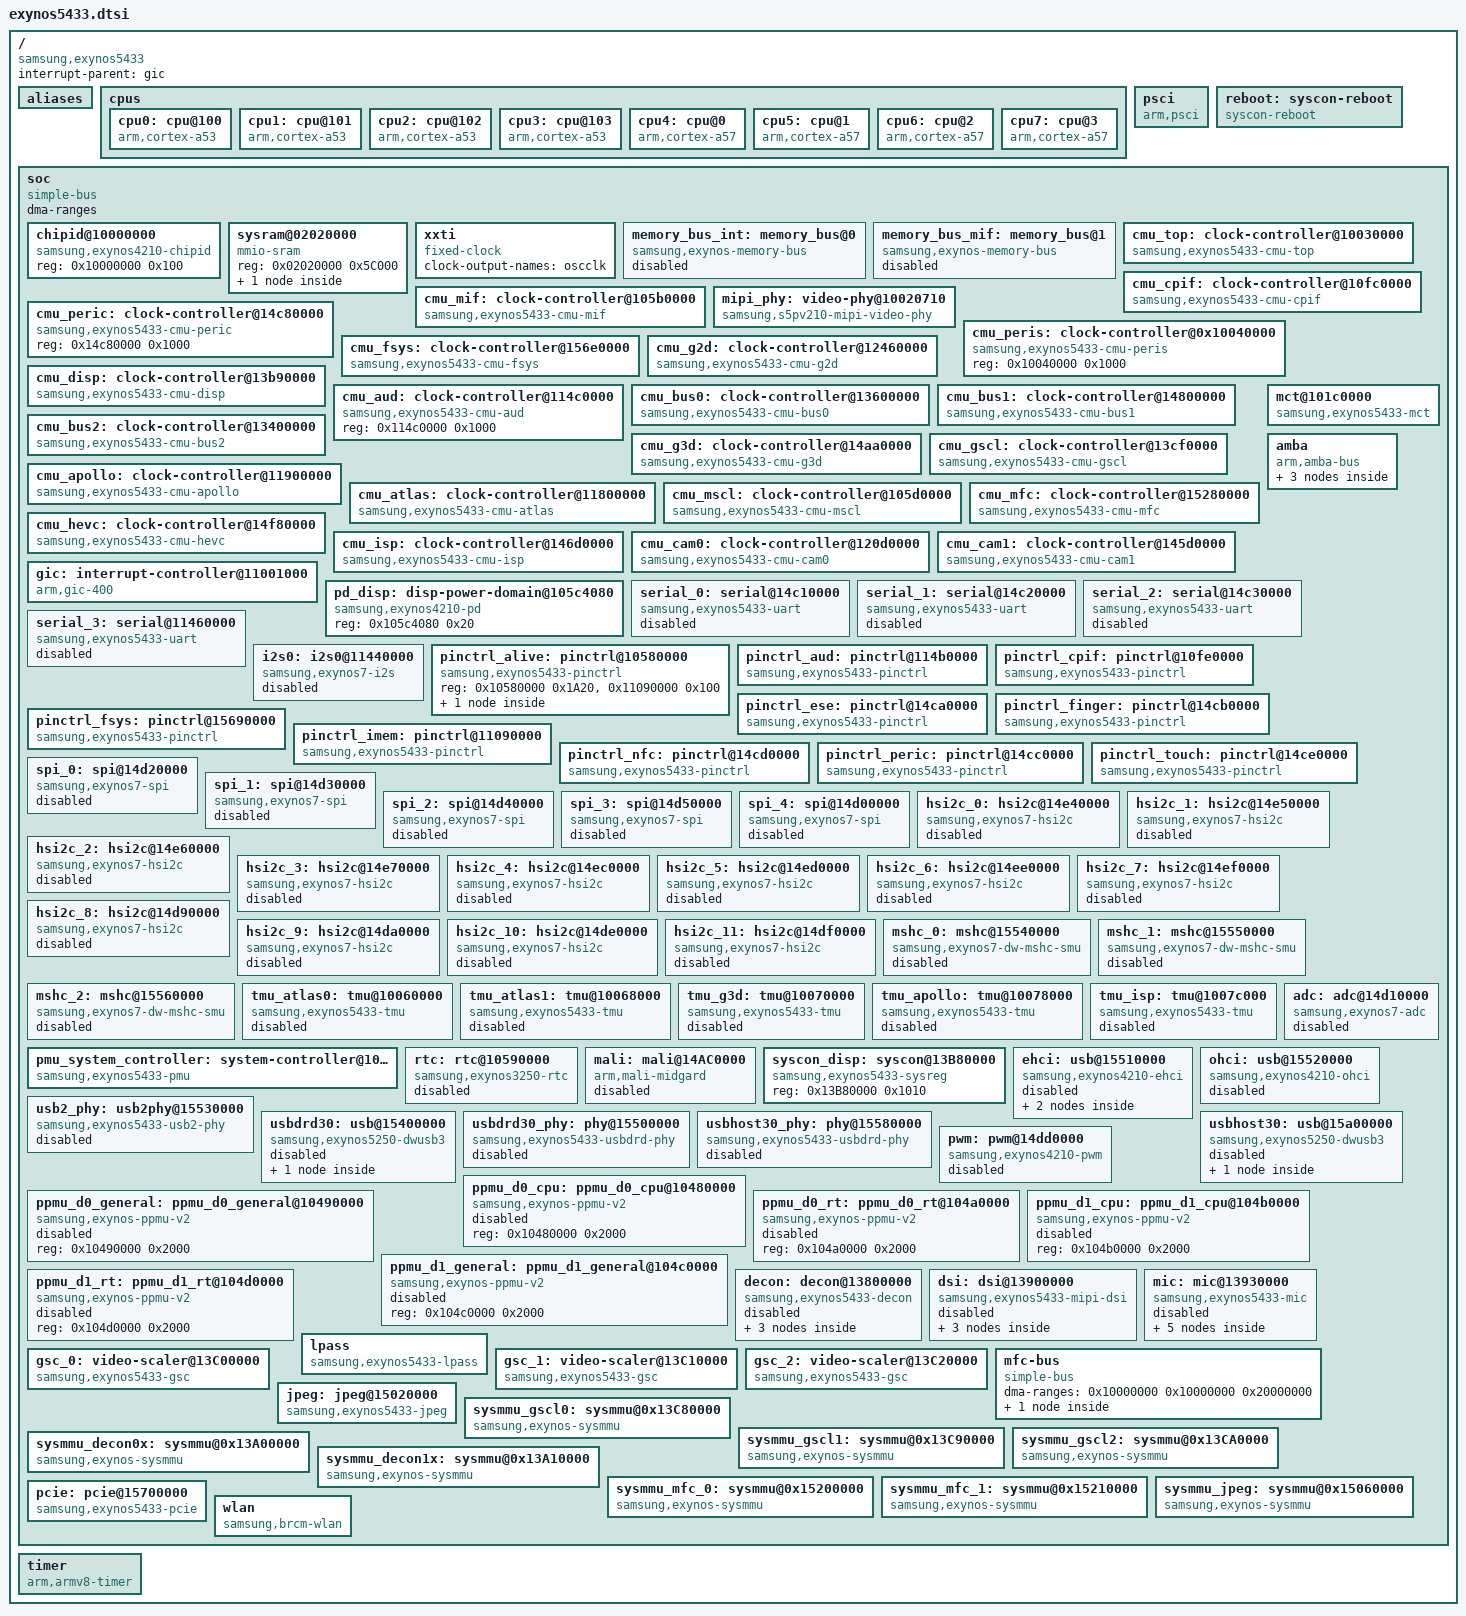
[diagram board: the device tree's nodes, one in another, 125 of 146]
/*
 * Samsung's Exynos5433 SoC device tree source
 *
 * Copyright (c) 2015 Samsung Electronics Co., Ltd.
 *		http://www.samsung.com
 *
 * Samsung's Exynos5433 SoC device nodes are listed in this file. Exynos5433
 * based board files can include this file and provide values for board specfic
 * bindings.
 *
 * Note: This file does not include device nodes for all the controllers in
 * Exynos5433 SoC. As device tree coverage for Exynos5433 increases, additional
 * nodes can be added to this file.
 *
 * This program is free software; you can redistribute it and/or modify
 * it under the terms of the GNU General Public License version 2 as
 * published by the Free Software Foundation.
 */

#include <dt-bindings/clock/exynos5433.h>

/ {
	compatible = "samsung,exynos5433";
	#address-cells = <2>;
	#size-cells = <2>;

	interrupt-parent = <&gic>;

	aliases {
		gsc0 = &gsc_0;
		gsc1 = &gsc_1;
		gsc2 = &gsc_2;
	};

	cpus {
		#address-cells = <1>;
		#size-cells = <0>;

		cpu0: cpu@100 {
			device_type = "cpu";
			compatible = "arm,cortex-a53", "arm,armv8";
			enable-method = "psci";
			reg = <0x100>;

			clocks = <&cmu_apollo CLK_SCLK_APOLLO>;
			clock-names = "cpu-cluster.1";
			clock-latency = <100000>;
			#cooling-cells = <2>;

			operating-points = <
				1300000 1150000
				1200000 1112500
				1100000 1112500
				1000000 1075000
				900000  1050000
				800000  1000000
				700000  975000
				600000  950000
				500000  925000
				400000  900000
			>;
			suspend-freq = <1200000>;
		};

		cpu1: cpu@101 {
			device_type = "cpu";
			compatible = "arm,cortex-a53", "arm,armv8";
			enable-method = "psci";
			reg = <0x101>;
		};

		cpu2: cpu@102 {
			device_type = "cpu";
			compatible = "arm,cortex-a53", "arm,armv8";
			enable-method = "psci";
			reg = <0x102>;
		};

		cpu3: cpu@103 {
			device_type = "cpu";
			compatible = "arm,cortex-a53", "arm,armv8";
			enable-method = "psci";
			reg = <0x103>;
		};

		cpu4: cpu@0 {
			device_type = "cpu";
			compatible = "arm,cortex-a57", "arm,armv8";
			enable-method = "psci";
			reg = <0x0>;

			clocks = <&cmu_atlas CLK_SCLK_ATLAS>;
			clock-names = "cpu-cluster.0";
			clock-latency = <100000>;
			#cooling-cells = <2>;

			operating-points = <
				1900000 1262500
				1800000 1212500
				1700000 1175000
				1600000 1137500
				1500000 1125000
				1400000 1087500
				1300000 1062500
				1200000 1037500
				1100000 1012500
				1000000 975000
				900000  937500
				800000  912500
				700000  912500
			>;
			suspend-freq = <1200000>;
		};

		cpu5: cpu@1 {
			device_type = "cpu";
			compatible = "arm,cortex-a57", "arm,armv8";
			enable-method = "psci";
			reg = <0x1>;
		};

		cpu6: cpu@2 {
			device_type = "cpu";
			compatible = "arm,cortex-a57", "arm,armv8";
			enable-method = "psci";
			reg = <0x2>;
		};

		cpu7: cpu@3 {
			device_type = "cpu";
			compatible = "arm,cortex-a57", "arm,armv8";
			enable-method = "psci";
			reg = <0x3>;
		};
	};

	psci {
		compatible = "arm,psci";
		method = "smc";
		cpu_suspend =  <0xC4000001>;
		cpu_off = <0x84000002>;
		cpu_on = <0xC4000003>;
	};

	reboot: syscon-reboot {
		compatible = "syscon-reboot";
		regmap = <&pmu_system_controller>;
		offset = <0x400>;
		mask = <0x1>;
	};

	soc: soc {
		compatible = "simple-bus";
		#address-cells = <1>;
		#size-cells = <1>;
		ranges = <0x0 0x0 0x0 0x18000000>;
		dma-ranges;

		chipid@10000000 {
			compatible = "samsung,exynos4210-chipid";
			reg = <0x10000000 0x100>;
		};

		sysram@02020000 {
			compatible = "mmio-sram";
			reg = <0x02020000 0x5C000>;
			#address-cells = <1>;
			#size-cells = <1>;
			ranges = <0 0x02020000 0x5C000>;

			smp-sysram@5B000 {
				compatible = "samsung,exynos5433-sysram-ns";
				reg = <0x5B000 0x1000>;
			};
		};

		xxti: xxti {
			compatible = "fixed-clock";
			clock-output-names = "oscclk";
			#clock-cells = <0>;
		};

		memory_bus_int: memory_bus@0 {
			compatible = "samsung,exynos-memory-bus";
			operating-points = <
				400000 1075000
				334000 1025000
				267000 1000000
				200000 975000
				160000 962500
				133000 950000
				100000 937500>;
			status = "disabled";
		};

		memory_bus_mif: memory_bus@1 {
			compatible = "samsung,exynos-memory-bus";
			operating-points = <
				825000 1050000
				667000 1000000
				543000 975000
				413000 950000
				272000 950000
				222000 950000
				167000 925000
				136000 900000
				109000 875000
				78000  875000>;
			status = "disabled";
		};

		cmu_top: clock-controller@10030000 {
			compatible = "samsung,exynos5433-cmu-top";
			reg = <0x10030000 0x1000>;
			#clock-cells = <1>;

			clock-names = "oscclk",
				"sclk_mphy_pll",
				"sclk_mfc_pll",
				"sclk_bus_pll";
			clocks = <&xxti>,
			       <&cmu_cpif CLK_SCLK_MPHY_PLL>,
			       <&cmu_mif CLK_SCLK_MFC_PLL>,
			       <&cmu_mif CLK_SCLK_BUS_PLL>;
		};

		cmu_cpif: clock-controller@10fc0000 {
			compatible = "samsung,exynos5433-cmu-cpif";
			reg = <0x10fc0000 0x1000>;
			#clock-cells = <1>;

			clock-names = "oscclk";
			clocks = <&xxti>;
		};

		cmu_mif: clock-controller@105b0000 {
			compatible = "samsung,exynos5433-cmu-mif";
			reg = <0x105b0000 0x2000>;
			#clock-cells = <1>;

			clock-names = "oscclk",
				"sclk_mphy_pll";
			clocks = <&xxti>,
			       <&cmu_cpif CLK_SCLK_MPHY_PLL>;
		};

		mipi_phy: video-phy@10020710 {
			compatible = "samsung,s5pv210-mipi-video-phy";
			reg = <0x10020710 8>;
			#phy-cells = <1>;
			syscon = <&pmu_system_controller>;
		};

		cmu_peric: clock-controller@14c80000 {
			compatible = "samsung,exynos5433-cmu-peric";
			reg = <0x14c80000 0x1000>;
			#clock-cells = <1>;
		};

		cmu_peris: clock-controller@0x10040000 {
			compatible = "samsung,exynos5433-cmu-peris";
			reg = <0x10040000 0x1000>;
			#clock-cells = <1>;
		};

		cmu_fsys: clock-controller@156e0000 {
			compatible = "samsung,exynos5433-cmu-fsys";
			reg = <0x156e0000 0x1000>;
			#clock-cells = <1>;

			clock-names = "oscclk",
				"sclk_ufs_mphy",
				"div_aclk_fsys_200",
				"sclk_pcie_100_fsys",
				"sclk_ufsunipro_fsys",
				"sclk_mmc2_fsys",
				"sclk_mmc1_fsys",
				"sclk_mmc0_fsys",
				"sclk_usbhost30_fsys",
				"sclk_usbdrd30_fsys";
			clocks = <&xxti>,
			       <&cmu_cpif CLK_SCLK_UFS_MPHY>,
			       <&cmu_top CLK_DIV_ACLK_FSYS_200>,
			       <&cmu_top CLK_SCLK_PCIE_100_FSYS>,
			       <&cmu_top CLK_SCLK_UFSUNIPRO_FSYS>,
			       <&cmu_top CLK_SCLK_MMC2_FSYS>,
			       <&cmu_top CLK_SCLK_MMC1_FSYS>,
			       <&cmu_top CLK_SCLK_MMC0_FSYS>,
			       <&cmu_top CLK_SCLK_USBHOST30_FSYS>,
			       <&cmu_top CLK_SCLK_USBDRD30_FSYS>;
		};

		cmu_g2d: clock-controller@12460000 {
			compatible = "samsung,exynos5433-cmu-g2d";
			reg = <0x12460000 0x1000>;
			#clock-cells = <1>;

			clock-names = "oscclk",
				"aclk_g2d_266",
				"aclk_g2d_400";
			clocks = <&xxti>,
			       <&cmu_top CLK_ACLK_G2D_266>,
			       <&cmu_top CLK_ACLK_G2D_400>;
		};

		cmu_disp: clock-controller@13b90000 {
			compatible = "samsung,exynos5433-cmu-disp";
			reg = <0x13b90000 0x1000>;
			#clock-cells = <1>;

			clock-names = "oscclk",
				"sclk_dsim1_disp",
				"sclk_dsim0_disp",
				"sclk_dsd_disp",
				"sclk_decon_tv_eclk_disp",
				"sclk_decon_vclk_disp",
				"sclk_decon_eclk_disp",
				"sclk_decon_tv_vclk_disp",
				"aclk_disp_333";
			clocks = <&xxti>,
			       <&cmu_mif CLK_SCLK_DSIM1_DISP>,
			       <&cmu_mif CLK_SCLK_DSIM0_DISP>,
			       <&cmu_mif CLK_SCLK_DSD_DISP>,
			       <&cmu_mif CLK_SCLK_DECON_TV_ECLK_DISP>,
			       <&cmu_mif CLK_SCLK_DECON_VCLK_DISP>,
			       <&cmu_mif CLK_SCLK_DECON_ECLK_DISP>,
			       <&cmu_mif CLK_SCLK_DECON_TV_VCLK_DISP>,
			       <&cmu_mif CLK_ACLK_DISP_333>;
			power-domains = <&pd_disp>;
		};

		cmu_aud: clock-controller@114c0000 {
			compatible = "samsung,exynos5433-cmu-aud";
			reg = <0x114c0000 0x1000>;
			#clock-cells = <1>;
		};

		cmu_bus0: clock-controller@13600000 {
			compatible = "samsung,exynos5433-cmu-bus0";
			reg = <0x13600000 0x1000>;
			#clock-cells = <1>;

			clock-names = "aclk_bus0_400";
			clocks = <&cmu_top CLK_ACLK_BUS0_400>;
		};

		cmu_bus1: clock-controller@14800000 {
			compatible = "samsung,exynos5433-cmu-bus1";
			reg = <0x14800000 0x1000>;
			#clock-cells = <1>;

			clock-names = "aclk_bus1_400";
			clocks = <&cmu_top CLK_ACLK_BUS1_400>;
		};

		cmu_bus2: clock-controller@13400000 {
			compatible = "samsung,exynos5433-cmu-bus2";
			reg = <0x13400000 0x1000>;
			#clock-cells = <1>;

			clock-names = "oscclk", "aclk_bus2_400";
			clocks = <&xxti>, <&cmu_mif CLK_ACLK_BUS2_400>;
		};

		cmu_g3d: clock-controller@14aa0000 {
			compatible = "samsung,exynos5433-cmu-g3d";
			reg = <0x14aa0000 0x2000>;
			#clock-cells = <1>;

			clock-names = "oscclk", "aclk_g3d_400";
			clocks = <&xxti>, <&cmu_top CLK_ACLK_G3D_400>;
		};

		cmu_gscl: clock-controller@13cf0000 {
			compatible = "samsung,exynos5433-cmu-gscl";
			reg = <0x13cf0000 0x1000>;
			#clock-cells = <1>;

			clock-names = "oscclk",
				"aclk_gscl_111",
				"aclk_gscl_333";
			clocks = <&xxti>,
				<&cmu_top CLK_ACLK_GSCL_111>,
				<&cmu_top CLK_ACLK_GSCL_333>;
		};

		cmu_apollo: clock-controller@11900000 {
			compatible = "samsung,exynos5433-cmu-apollo";
			reg = <0x11900000 0x2000>;
			#clock-cells = <1>;

			clock-names = "oscclk", "sclk_bus_pll_apollo";
			clocks = <&xxti>, <&cmu_mif CLK_SCLK_BUS_PLL_APOLLO>;
		};

		cmu_atlas: clock-controller@11800000 {
			compatible = "samsung,exynos5433-cmu-atlas";
			reg = <0x11800000 0x2000>;
			#clock-cells = <1>;

			clock-names = "oscclk", "sclk_bus_pll_atlas";
			clocks = <&xxti>, <&cmu_mif CLK_SCLK_BUS_PLL_ATLAS>;
		};

		cmu_mscl: clock-controller@105d0000 {
			compatible = "samsung,exynos5433-cmu-mscl";
			reg = <0x150d0000 0x1000>;
			#clock-cells = <1>;

			clock-names = "oscclk",
				"sclk_jpeg_mscl",
				"aclk_mscl_400";
			clocks = <&xxti>,
			       <&cmu_top CLK_SCLK_JPEG_MSCL>,
			       <&cmu_top CLK_ACLK_MSCL_400>;
		};

		cmu_mfc: clock-controller@15280000 {
			compatible = "samsung,exynos5433-cmu-mfc";
			reg = <0x15280000 0x1000>;
			#clock-cells = <1>;

			clock-names = "oscclk", "aclk_mfc_400";
			clocks = <&xxti>, <&cmu_top CLK_ACLK_MFC_400>;
		};

		cmu_hevc: clock-controller@14f80000 {
			compatible = "samsung,exynos5433-cmu-hevc";
			reg = <0x14f80000 0x1000>;
			#clock-cells = <1>;

			clock-names = "oscclk", "aclk_hevc_400";
			clocks = <&xxti>, <&cmu_top CLK_ACLK_HEVC_400>;
		};

		cmu_isp: clock-controller@146d0000 {
			compatible = "samsung,exynos5433-cmu-isp";
			reg = <0x146d0000 0x1000>;
			#clock-cells = <1>;

			clock-names = "oscclk",
				"aclk_isp_dis_400",
				"aclk_isp_400";
			clocks = <&xxti>,
			       <&cmu_top CLK_ACLK_ISP_DIS_400>,
			       <&cmu_top CLK_ACLK_ISP_400>;
		};

		cmu_cam0: clock-controller@120d0000 {
			compatible = "samsung,exynos5433-cmu-cam0";
			reg = <0x120d0000 0x1000>;
			#clock-cells = <1>;

			clock-names = "oscclk",
				"aclk_cam0_333",
				"aclk_cam0_400",
				"aclk_cam0_552";
			clocks = <&xxti>,
			       <&cmu_top CLK_ACLK_CAM0_333>,
			       <&cmu_top CLK_ACLK_CAM0_400>,
			       <&cmu_top CLK_ACLK_CAM0_552>;
		};

		cmu_cam1: clock-controller@145d0000 {
			compatible = "samsung,exynos5433-cmu-cam1";
			reg = <0x145d0000 0x1000>;
			#clock-cells = <1>;

			clock-names = "oscclk",
				"sclk_isp_uart_cam1",
				"sclk_isp_spi1_cam1",
				"sclk_isp_spi0_cam1",
				"aclk_cam1_333",
				"aclk_cam1_400",
				"aclk_cam1_552";
			clocks = <&xxti>,
			       <&cmu_top CLK_SCLK_ISP_UART_CAM1>,
			       <&cmu_top CLK_SCLK_ISP_SPI1_CAM1>,
			       <&cmu_top CLK_SCLK_ISP_SPI0_CAM1>,
			       <&cmu_top CLK_ACLK_CAM1_333>,
			       <&cmu_top CLK_ACLK_CAM1_400>,
			       <&cmu_top CLK_ACLK_CAM1_552>;
		};

		mct@101c0000 {
			compatible = "samsung,exynos5433-mct",
				     "samsung,exynos4210-mct";
			reg = <0x101c0000 0x800>;
			interrupts = <0 102 0>, <0 103 0>, <0 104 0>, <0 105 0>,
				<0 106 0>, <0 107 0>, <0 108 0>, <0 109 0>,
				<0 110 0>, <0 111 0>, <0 112 0>, <0 113 0>;
			clocks = <&xxti>,
			         <&cmu_peris CLK_PCLK_MCT>;
			clock-names = "fin_pll", "mct";
		};

		gic:interrupt-controller@11001000 {
			compatible = "arm,gic-400";
			#interrupt-cells = <3>;
			interrupt-controller;
			reg =	<0x11001000 0x1000>,
				<0x11002000 0x2000>,
				<0x11004000 0x2000>,
				<0x11006000 0x2000>;
			interrupts = <1 9 0xf04>;
		};

		amba {
			compatible = "arm,amba-bus";
			#address-cells = <1>;
			#size-cells = <1>;
			ranges;

			pdma0: pdma@15610000 {
				compatible = "arm,pl330", "arm,primecell";
				reg = <0x15610000 0x1000>;
				interrupts = <0 228 0>;
				clocks = <&cmu_fsys CLK_PDMA0>;
				clock-names = "apb_pclk";
				#dma-cells = <1>;
				#dma-channels = <8>;
				#dma-requests = <32>;
			};

			pdma1: pdma@15600000 {
				compatible = "arm,pl330", "arm,primecell";
				reg = <0x15600000 0x1000>;
				interrupts = <0 246 0>;
				clocks = <&cmu_fsys CLK_PDMA1>;
				clock-names = "apb_pclk";
				#dma-cells = <1>;
				#dma-channels = <8>;
				#dma-requests = <32>;
			};

			adma: adma@11420000 {
				compatible = "arm,pl330", "arm,primecell";
				reg = <0x11420000 0x1000>;
				interrupts = <0 73 0>;
				clocks = <&cmu_aud CLK_ACLK_DMAC>;
				clock-names = "apb_pclk";
				#dma-cells = <1>;
				#dma-channels = <8>;
				#dma-requests = <32>;
			};
		};

		pd_disp: disp-power-domain@105c4080 {
			compatible = "samsung,exynos4210-pd";
			reg = <0x105c4080 0x20>;
			#power-domain-cells = <0>;
		};

		serial_0: serial@14c10000 {
			compatible = "samsung,exynos5433-uart";
			reg = <0x14c10000 0x100>;
			interrupts = <0 421 0>;
			clocks = <&cmu_peric CLK_PCLK_UART0>,
				 <&cmu_peric CLK_SCLK_UART0>;
			clock-names = "uart", "clk_uart_baud0";
			pinctrl-names = "default";
			pinctrl-0 = <&uart0_bus>;
			status = "disabled";
		};

		serial_1: serial@14c20000 {
			compatible = "samsung,exynos5433-uart";
			reg = <0x14c20000 0x100>;
			interrupts = <0 422 0>;
			clocks = <&cmu_peric CLK_PCLK_UART1>,
				 <&cmu_peric CLK_SCLK_UART1>;
			clock-names = "uart", "clk_uart_baud0";
			pinctrl-names = "default";
			pinctrl-0 = <&uart1_bus>;
			status = "disabled";
		};

		serial_2: serial@14c30000 {
			compatible = "samsung,exynos5433-uart";
			reg = <0x14c30000 0x100>;
			interrupts = <0 423 0>;
			clocks = <&cmu_peric CLK_PCLK_UART2>,
				 <&cmu_peric CLK_SCLK_UART2>;
			clock-names = "uart", "clk_uart_baud0";
			pinctrl-names = "default";
			pinctrl-0 = <&uart2_bus>;
			status = "disabled";
		};

		serial_3: serial@11460000 {
			compatible = "samsung,exynos5433-uart";
			reg = <0x11460000 0x100>;
			interrupts = <0 67 0>;
			clocks = <&cmu_aud CLK_PCLK_AUD_UART>,
				 <&cmu_aud CLK_SCLK_AUD_UART>;
			clock-names = "uart", "clk_uart_baud0";
			pinctrl-names = "default";
			pinctrl-0 = <&uart_aud_bus>;
			status = "disabled";
		};

		i2s0: i2s0@11440000 {
			compatible = "samsung,exynos7-i2s";
			reg = <0x11440000 0x100>;
			dmas = <&adma 0 &adma 2>;
			dma-names = "tx", "rx";
			interrupts = <0 70 0>;
			#address-cells = <1>;
			#size-cells = <0>;
			clocks = <&cmu_aud CLK_PCLK_AUD_I2S>,
				 <&cmu_aud CLK_SCLK_AUD_I2S>,
				 <&cmu_aud CLK_SCLK_I2S_BCLK>;
			clock-names = "iis", "i2s_opclk0", "i2s_opclk1";
			pinctrl-names = "default";
			pinctrl-0 = <&i2s0_bus>;
			status = "disabled";
		};

		pinctrl_alive: pinctrl@10580000 {
			compatible = "samsung,exynos5433-pinctrl";
			reg = <0x10580000 0x1A20>, <0x11090000 0x100>;

			wakeup-interrupt-controller {
				compatible = "samsung,exynos7-wakeup-eint";
				interrupts = <0 16 0>;
			};
		};

		pinctrl_aud: pinctrl@114b0000 {
			compatible = "samsung,exynos5433-pinctrl";
			reg = <0x114b0000 0x1000>;
			interrupts = <0 68 0>;
		};

		pinctrl_cpif: pinctrl@10fe0000 {
			compatible = "samsung,exynos5433-pinctrl";
			reg = <0x10fe0000 0x1000>;
			interrupts = <0 179 0>;
		};

		pinctrl_ese: pinctrl@14ca0000 {
			compatible = "samsung,exynos5433-pinctrl";
			reg = <0x14ca0000 0x1000>;
			interrupts = <0 413 0>;
		};

		pinctrl_finger: pinctrl@14cb0000 {
			compatible = "samsung,exynos5433-pinctrl";
			reg = <0x14cb0000 0x1000>;
			interrupts = <0 414 0>;
		};

		pinctrl_fsys: pinctrl@15690000 {
			compatible = "samsung,exynos5433-pinctrl";
			reg = <0x15690000 0x1000>;
			interrupts = <0 229 0>;
		};

		pinctrl_imem: pinctrl@11090000 {
			compatible = "samsung,exynos5433-pinctrl";
			reg = <0x11090000 0x1000>;
			interrupts = <0 325 0>;
		};

		pinctrl_nfc: pinctrl@14cd0000 {
			compatible = "samsung,exynos5433-pinctrl";
			reg = <0x14cd0000 0x1000>;
			interrupts = <0 441 0>;
		};

		pinctrl_peric: pinctrl@14cc0000 {
			compatible = "samsung,exynos5433-pinctrl";
			reg = <0x14cc0000 0x1100>;
			interrupts = <0 440 0>;
		};

		pinctrl_touch: pinctrl@14ce0000 {
			compatible = "samsung,exynos5433-pinctrl";
			reg = <0x14ce0000 0x1100>;
			interrupts = <0 442 0>;
		};

		spi_0: spi@14d20000 {
			compatible = "samsung,exynos7-spi";
			reg = <0x14d20000 0x100>;
			interrupts = <0 432 0>;
			dmas = <&pdma0 9>, <&pdma0 8>;
			dma-names = "tx", "rx";
			#address-cells = <1>;
			#size-cells = <0>;
			clocks = <&cmu_peric CLK_PCLK_SPI0>,
				 <&cmu_top CLK_SCLK_SPI0_PERIC>;
			clock-names = "spi", "spi_busclk0";
			samsung,spi-src-clk = <0>;
			pinctrl-names = "default";
			pinctrl-0 = <&spi0_bus>;
			status = "disabled";
		};

		spi_1: spi@14d30000 {
			compatible = "samsung,exynos7-spi";
			reg = <0x14d30000 0x100>;
			interrupts = <0 433 0>;
			dmas = <&pdma0 11>, <&pdma0 10>;
			dma-names = "tx", "rx";
			#address-cells = <1>;
			#size-cells = <0>;
			clocks = <&cmu_peric CLK_PCLK_SPI1>,
				 <&cmu_top CLK_SCLK_SPI1_PERIC>;
			clock-names = "spi", "spi_busclk0";
			samsung,spi-src-clk = <0>;
			pinctrl-names = "default";
			pinctrl-0 = <&spi1_bus>;
			status = "disabled";
		};

		spi_2: spi@14d40000 {
			compatible = "samsung,exynos7-spi";
			reg = <0x14d40000 0x100>;
			interrupts = <0 434 0>;
			dmas = <&pdma0 13>, <&pdma0 12>;
			dma-names = "tx", "rx";
			#address-cells = <1>;
			#size-cells = <0>;
			clocks = <&cmu_peric CLK_PCLK_SPI2>,
				 <&cmu_top CLK_SCLK_SPI2_PERIC>;
			clock-names = "spi", "spi_busclk0";
			samsung,spi-src-clk = <0>;
			pinctrl-names = "default";
			pinctrl-0 = <&spi2_bus>;
			status = "disabled";
		};

		spi_3: spi@14d50000 {
			compatible = "samsung,exynos7-spi";
			reg = <0x14d50000 0x100>;
			interrupts = <0 447 0>;
			dmas = <&pdma0 23>, <&pdma0 22>;
			dma-names = "tx", "rx";
			#address-cells = <1>;
			#size-cells = <0>;
			clocks = <&cmu_peric CLK_PCLK_SPI3>,
				 <&cmu_top CLK_SCLK_SPI3_PERIC>;
			clock-names = "spi", "spi_busclk0";
			samsung,spi-src-clk = <0>;
			pinctrl-names = "default";
			pinctrl-0 = <&spi3_bus>;
			status = "disabled";
		};

		spi_4: spi@14d00000 {
			compatible = "samsung,exynos7-spi";
			reg = <0x14d00000 0x100>;
			interrupts = <0 412 0>;
			dmas = <&pdma0 25>, <&pdma0 24>;
			dma-names = "tx", "rx";
			#address-cells = <1>;
			#size-cells = <0>;
			clocks = <&cmu_peric CLK_PCLK_SPI4>,
				 <&cmu_top CLK_SCLK_SPI4_PERIC>;
			clock-names = "spi", "spi_busclk0";
			samsung,spi-src-clk = <0>;
			pinctrl-names = "default";
			pinctrl-0 = <&spi4_bus>;
			status = "disabled";
		};

		hsi2c_0: hsi2c@14e40000 {
			compatible = "samsung,exynos7-hsi2c";
			reg = <0x14e40000 0x1000>;
			interrupts = <0 428 0>;
			#address-cells = <1>;
			#size-cells = <0>;
			pinctrl-names = "default";
			pinctrl-0 = <&hs_i2c0_bus>;
			clocks = <&cmu_peric CLK_PCLK_HSI2C0>;
			clock-names = "hsi2c";
			status = "disabled";
		};

		hsi2c_1: hsi2c@14e50000 {
			compatible = "samsung,exynos7-hsi2c";
			reg = <0x14e50000 0x1000>;
			interrupts = <0 429 0>;
			#address-cells = <1>;
			#size-cells = <0>;
			pinctrl-names = "default";
			pinctrl-0 = <&hs_i2c1_bus>;
			clocks = <&cmu_peric CLK_PCLK_HSI2C1>;
			clock-names = "hsi2c";
			status = "disabled";
		};

		hsi2c_2: hsi2c@14e60000 {
			compatible = "samsung,exynos7-hsi2c";
			reg = <0x14e60000 0x1000>;
			interrupts = <0 430 0>;
			#address-cells = <1>;
			#size-cells = <0>;
			pinctrl-names = "default";
			pinctrl-0 = <&hs_i2c2_bus>;
			clocks = <&cmu_peric CLK_PCLK_HSI2C2>;
			clock-names = "hsi2c";
			status = "disabled";
		};

		hsi2c_3: hsi2c@14e70000 {
			compatible = "samsung,exynos7-hsi2c";
			reg = <0x14e70000 0x1000>;
			interrupts = <0 431 0>;
			#address-cells = <1>;
			#size-cells = <0>;
			pinctrl-names = "default";
			pinctrl-0 = <&hs_i2c3_bus>;
			clocks = <&cmu_peric CLK_PCLK_HSI2C3>;
			clock-names = "hsi2c";
			status = "disabled";
		};

		hsi2c_4: hsi2c@14ec0000 {
			compatible = "samsung,exynos7-hsi2c";
			reg = <0x14ec0000 0x1000>;
			interrupts = <0 424 0>;
			#address-cells = <1>;
			#size-cells = <0>;
			pinctrl-names = "default";
			pinctrl-0 = <&hs_i2c4_bus>;
			clocks = <&cmu_peric CLK_PCLK_HSI2C4>;
			clock-names = "hsi2c";
			status = "disabled";
		};

		hsi2c_5: hsi2c@14ed0000 {
			compatible = "samsung,exynos7-hsi2c";
			reg = <0x14ed0000 0x1000>;
			interrupts = <0 425 0>;
			#address-cells = <1>;
			#size-cells = <0>;
			pinctrl-names = "default";
			pinctrl-0 = <&hs_i2c5_bus>;
			clocks = <&cmu_peric CLK_PCLK_HSI2C5>;
			clock-names = "hsi2c";
			status = "disabled";
		};

		hsi2c_6: hsi2c@14ee0000 {
			compatible = "samsung,exynos7-hsi2c";
			reg = <0x14ee0000 0x1000>;
			interrupts = <0 426 0>;
			#address-cells = <1>;
			#size-cells = <0>;
			pinctrl-names = "default";
			pinctrl-0 = <&hs_i2c6_bus>;
			clocks = <&cmu_peric CLK_PCLK_HSI2C6>;
			clock-names = "hsi2c";
			status = "disabled";
		};

		hsi2c_7: hsi2c@14ef0000 {
			compatible = "samsung,exynos7-hsi2c";
			reg = <0x14ef0000 0x1000>;
			interrupts = <0 427 0>;
			#address-cells = <1>;
			#size-cells = <0>;
			pinctrl-names = "default";
			pinctrl-0 = <&hs_i2c7_bus>;
			clocks = <&cmu_peric CLK_PCLK_HSI2C7>;
			clock-names = "hsi2c";
			status = "disabled";
		};

		hsi2c_8: hsi2c@14d90000 {
			compatible = "samsung,exynos7-hsi2c";
			reg = <0x14d90000 0x1000>;
			interrupts = <0 443 0>;
			#address-cells = <1>;
			#size-cells = <0>;
			pinctrl-names = "default";
			pinctrl-0 = <&hs_i2c8_bus>;
			clocks = <&cmu_peric CLK_PCLK_HSI2C8>;
			clock-names = "hsi2c";
			status = "disabled";
		};

		hsi2c_9: hsi2c@14da0000 {
			compatible = "samsung,exynos7-hsi2c";
			reg = <0x14da0000 0x1000>;
			interrupts = <0 444 0>;
			#address-cells = <1>;
			#size-cells = <0>;
			pinctrl-names = "default";
			pinctrl-0 = <&hs_i2c9_bus>;
			clocks = <&cmu_peric CLK_PCLK_HSI2C9>;
			clock-names = "hsi2c";
			status = "disabled";
		};

		hsi2c_10: hsi2c@14de0000 {
			compatible = "samsung,exynos7-hsi2c";
			reg = <0x14de0000 0x1000>;
			interrupts = <0 445 0>;
			#address-cells = <1>;
			#size-cells = <0>;
			pinctrl-names = "default";
			pinctrl-0 = <&hs_i2c10_bus>;
			clocks = <&cmu_peric CLK_PCLK_HSI2C10>;
			clock-names = "hsi2c";
			status = "disabled";
		};

		hsi2c_11: hsi2c@14df0000 {
			compatible = "samsung,exynos7-hsi2c";
			reg = <0x14df0000 0x1000>;
			interrupts = <0 446 0>;
			#address-cells = <1>;
			#size-cells = <0>;
			pinctrl-names = "default";
			pinctrl-0 = <&hs_i2c11_bus>;
			clocks = <&cmu_peric CLK_PCLK_HSI2C11>;
			clock-names = "hsi2c";
			status = "disabled";
		};

		mshc_0: mshc@15540000 {
			compatible = "samsung,exynos7-dw-mshc-smu";
			interrupts = <0 225 0>;
			#address-cells = <1>;
			#size-cells = <0>;
			reg = <0x15540000 0x2000>;
			clocks = <&cmu_fsys CLK_ACLK_MMC0>,
				 <&cmu_fsys CLK_SCLK_MMC0>;
			clock-names = "biu", "ciu";
			fifo-depth = <0x40>;
			status = "disabled";
		};

		mshc_1: mshc@15550000 {
			compatible = "samsung,exynos7-dw-mshc-smu";
			interrupts = <0 226 0>;
			#address-cells = <1>;
			#size-cells = <0>;
			reg = <0x15550000 0x2000>;
			clocks = <&cmu_fsys CLK_ACLK_MMC1>,
				 <&cmu_fsys CLK_SCLK_MMC1>;
			clock-names = "biu", "ciu";
			fifo-depth = <0x40>;
			status = "disabled";
		};

		mshc_2: mshc@15560000 {
			compatible = "samsung,exynos7-dw-mshc-smu";
			interrupts = <0 227 0>;
			#address-cells = <1>;
			#size-cells = <0>;
			reg = <0x15560000 0x2000>;
			clocks = <&cmu_fsys CLK_ACLK_MMC2>,
				 <&cmu_fsys CLK_SCLK_MMC2>;
			clock-names = "biu", "ciu";
			fifo-depth = <0x40>;
			status = "disabled";
		};

		tmu_atlas0: tmu@10060000 {
			compatible = "samsung,exynos5433-tmu";
			reg = <0x10060000 0x200>;
			interrupts = <0 95 0>;
			clocks = <&cmu_peris CLK_PCLK_TMU0_APBIF>,
				 <&cmu_peris CLK_SCLK_TMU0>;
			clock-names = "tmu_apbif", "tmu_sclk";
			#include "exynos5433-tmu-sensor-conf.dtsi"
			status = "disabled";
		};

		tmu_atlas1: tmu@10068000 {
			compatible = "samsung,exynos5433-tmu";
			reg = <0x10068000 0x200>;
			interrupts = <0 96 0>;
			clocks = <&cmu_peris CLK_PCLK_TMU0_APBIF>,
				 <&cmu_peris CLK_SCLK_TMU0>;
			clock-names = "tmu_apbif", "tmu_sclk";
			#include "exynos5433-tmu-sensor-conf.dtsi"
			status = "disabled";
		};

		tmu_g3d: tmu@10070000 {
			compatible = "samsung,exynos5433-tmu";
			reg = <0x10070000 0x200>;
			interrupts = <0 99 0>;
			clocks = <&cmu_peris CLK_PCLK_TMU1_APBIF>,
				 <&cmu_peris CLK_SCLK_TMU1>;
			clock-names = "tmu_apbif", "tmu_sclk";
			#include "exynos5433-tmu-sensor-conf.dtsi"
			status = "disabled";
		};

		tmu_apollo: tmu@10078000 {
			compatible = "samsung,exynos5433-tmu";
			reg = <0x10078000 0x200>;
			interrupts = <0 115 0>;
			clocks = <&cmu_peris CLK_PCLK_TMU1_APBIF>,
				 <&cmu_peris CLK_SCLK_TMU1>;
			clock-names = "tmu_apbif", "tmu_sclk";
			#include "exynos5433-tmu-sensor-conf.dtsi"
			status = "disabled";
		};

		tmu_isp: tmu@1007c000 {
			compatible = "samsung,exynos5433-tmu";
			reg = <0x1007c000 0x200>;
			interrupts = <0 94 0>;
			clocks = <&cmu_peris CLK_PCLK_TMU1_APBIF>,
				 <&cmu_peris CLK_SCLK_TMU1>;
			clock-names = "tmu_apbif", "tmu_sclk";
			#include "exynos5433-tmu-sensor-conf.dtsi"
			status = "disabled";
		};

		pmu_system_controller: system-controller@105c0000 {
			compatible = "samsung,exynos5433-pmu", "syscon";
			reg = <0x105c0000 0x5008>;
			#clock-cells = <1>;
			clock-names = "clkout16";
			clocks = <&xxti>;
		};

		rtc: rtc@10590000 {
			compatible = "samsung,exynos3250-rtc";
			reg = <0x10590000 0x100>;
			#clock-cells = <1>;
			clocks = <&cmu_mif CLK_PCLK_RTC>, <&s2mps13_osc 0>;
			clock-names = "rtc", "rtc_src";
			interrupts = <0 385 0>, <0 386 0>;
			status = "disabled";
		};

		mali: mali@14AC0000 {
			compatible = "arm,mali-midgard";
			reg = <0x14AC0000 0x5000>;
			interrupts = <0 282 0>, <0 283 0>, <0 281 0>;
			interrupt-names = "JOB", "MMU", "GPU";
			clocks = <&cmu_g3d CLK_ACLK_G3D>;
			clock-names = "clk_mali";
			status = "disabled";

			assigned-clocks = <&cmu_g3d CLK_FOUT_G3D_PLL>;
			assigned-clock-rates = <160000000>;

			operating-points = <
				700000 1150000
				600000 1150000
				550000 1125000
				500000 1075000
				420000 1025000
				350000 1025000
				266000 1000000
				160000 1000000
			>;
		};

		syscon_disp: syscon@13B80000 {
			compatible = "samsung,exynos5433-sysreg", "syscon";
			reg = <0x13B80000 0x1010>;
		};

		adc: adc@14d10000 {
			compatible = "samsung,exynos7-adc";
			reg = <0x14d10000 0x100>;
			interrupts = <0 438 0>;
			clock-names = "adc";
			clocks = <&cmu_peric CLK_PCLK_ADCIF>;
			#io-channel-cells = <1>;
			io-channel-ranges;
			status = "disabled";
		};

		ehci: usb@15510000 {
			compatible = "samsung,exynos4210-ehci";
			reg = <0x15510000 0x1000>;
			interrupts = <0 230 0>;
			clocks = <&cmu_fsys CLK_ACLK_USBHOST20>;
			clock-names = "usbhost";
			#address-cells = <1>;
			#size-cells = <0>;
			status = "disabled";

			port@0 {
				reg = <0>;
				phys = <&usb2_phy 0>;
				status = "disabled";
			};
			port@1 {
				reg = <1>;
				phys = <&usb2_phy 1>;
				status = "disabled";
			};
		};

		ohci: usb@15520000 {
			compatible = "samsung,exynos4210-ohci";
			reg = <0x15520000 0x1000>;
			interrupts = <0 230 0>;
			clocks = <&cmu_fsys CLK_ACLK_USBHOST20>;
			clock-names = "usbhost";
			#address-cells = <1>;
			#size-cells = <0>;
			status = "disabled";
		};

		usb2_phy: usb2phy@15530000 {
			compatible = "samsung,exynos5433-usb2-phy";
			reg = <0x15530000 0x100>;
			samsung,pmureg-phandle = <&pmu_system_controller>;
			clocks = <&cmu_fsys CLK_ACLK_USBHOST20>, <&xxti>;
			clock-names = "phy", "ref";
			#phy-cells = <1>;
			status = "disabled";
		};

		usbdrd30: usb@15400000 {
			compatible = "samsung,exynos5250-dwusb3";
			clocks = <&cmu_fsys CLK_ACLK_USBDRD30>,
				<&cmu_fsys CLK_SCLK_USBDRD30>;
			clock-names = "usbdrd30", "usbdrd30_susp_clk";
			assigned-clocks =
				<&cmu_fsys CLK_MOUT_SCLK_USBDRD30_USER>,
				<&cmu_top CLK_MOUT_SCLK_USBDRD30>,
				<&cmu_top CLK_DIV_SCLK_USBDRD30>;
			assigned-clock-parents =
				<&cmu_top CLK_SCLK_USBDRD30_FSYS>,
				<&cmu_top CLK_MOUT_BUS_PLL_USER>;
			assigned-clock-rates = <0>, <0>, <66700000>;
			#address-cells = <1>;
			#size-cells = <1>;
			ranges;
			status = "disabled";

			usbdrd_dwc3_0: dwc3 {
				compatible = "snps,dwc3";
				reg = <0x15400000 0x10000>;
				interrupts = <0 231 0>;
				phys = <&usbdrd30_phy 0>, <&usbdrd30_phy 1>;
				phy-names = "usb2-phy", "usb3-phy";
				snps,usb3_lpm_capable;
				snps,dis_u3_susphy_quirk;
				snps,dis_u2_susphy_quirk;
			};

		};

		usbdrd30_phy: phy@15500000 {
			compatible = "samsung,exynos5433-usbdrd-phy";
			reg = <0x15500000 0x100>;
			clocks = <&cmu_fsys CLK_ACLK_USBDRD30>, <&xxti>,
				<&cmu_fsys CLK_PHYCLK_USBDRD30_UDRD30_PHYCLOCK>,
				<&cmu_fsys CLK_PHYCLK_USBDRD30_UDRD30_PIPE_PCLK>,
				<&cmu_fsys CLK_SCLK_USBDRD30>;
			clock-names = "phy", "ref", "phy_utmi", "phy_pipe", "itp";
			assigned-clocks =
				<&cmu_fsys CLK_MOUT_PHYCLK_USBDRD30_UDRD30_PIPE_PCLK_USER>,
				<&cmu_fsys CLK_MOUT_PHYCLK_USBDRD30_UDRD30_PHYCLOCK_USER>;
			assigned-clock-parents =
				<&cmu_fsys CLK_PHYCLK_USBDRD30_UDRD30_PIPE_PCLK_PHY>,
				<&cmu_fsys CLK_PHYCLK_USBDRD30_UDRD30_PHYCLOCK_PHY>;
			#phy-cells = <1>;
			samsung,pmu-syscon = <&pmu_system_controller>;
			status = "disabled";
		};

		usbhost30_phy: phy@15580000 {
			compatible = "samsung,exynos5433-usbdrd-phy";
			reg = <0x15580000 0x100>;
			clocks = <&cmu_fsys CLK_ACLK_USBHOST30>, <&xxti>,
				<&cmu_fsys CLK_PHYCLK_USBHOST30_UHOST30_PHYCLOCK>,
				<&cmu_fsys CLK_PHYCLK_USBHOST30_UHOST30_PIPE_PCLK>,
				<&cmu_fsys CLK_SCLK_USBHOST30>;
			clock-names = "phy", "ref", "phy_utmi", "phy_pipe", "itp";
			assigned-clocks =
				<&cmu_fsys CLK_MOUT_PHYCLK_USBHOST30_UHOST30_PIPE_PCLK_USER>,
				<&cmu_fsys CLK_MOUT_PHYCLK_USBHOST30_UHOST30_PHYCLOCK_USER>;
			assigned-clock-parents =
				<&cmu_fsys CLK_PHYCLK_USBHOST30_UHOST30_PIPE_PCLK_PHY>,
				<&cmu_fsys CLK_PHYCLK_USBHOST30_UHOST30_PHYCLOCK_PHY>;
			#phy-cells = <1>;
			samsung,pmu-syscon = <&pmu_system_controller>;
			status = "disabled";
		};

		usbhost30: usb@15a00000 {
			compatible = "samsung,exynos5250-dwusb3";
			clocks = <&cmu_fsys CLK_ACLK_USBHOST30>,
				<&cmu_fsys CLK_SCLK_USBHOST30>;
			clock-names = "usbdrd30", "usbdrd30_susp_clk";
			assigned-clocks =
				<&cmu_fsys CLK_MOUT_SCLK_USBHOST30_USER>,
				<&cmu_top CLK_MOUT_SCLK_USBHOST30>,
				<&cmu_top CLK_DIV_SCLK_USBHOST30>;
			assigned-clock-parents =
				<&cmu_top CLK_SCLK_USBHOST30_FSYS>,
				<&cmu_top CLK_MOUT_BUS_PLL_USER>;
			assigned-clock-rates = <0>, <0>, <66700000>;
			#address-cells = <1>;
			#size-cells = <1>;
			ranges;
			status = "disabled";

			dwc3 {
				compatible = "snps,dwc3";
				reg = <0x154a0000 0x10000>;
				interrupts = <0 244 0>;
				phys = <&usbhost30_phy 0>, <&usbhost30_phy 1>;
				phy-names = "usb2-phy", "usb3-phy";
				snps,usb3_lpm_capable;
				snps,dis_u3_susphy_quirk;
				snps,dis_u2_susphy_quirk;
			};
		};

		pwm: pwm@14dd0000 {
			compatible = "samsung,exynos4210-pwm";
			reg = <0x14dd0000 0x100>;
			interrupts = <0 416 0>, <0 417 0>,
				     <0 418 0>, <0 419 0>, <0 420 0>;
			samsung,pwm-outputs = <0>, <1>, <2>, <3>;
			clocks = <&cmu_peric CLK_PCLK_PWM>;
			clock-names = "timers";
			#pwm-cells = <3>;
			status = "disabled";
		};

		ppmu_d0_cpu: ppmu_d0_cpu@10480000 {
			compatible = "samsung,exynos-ppmu-v2";
			reg = <0x10480000 0x2000>;
			status = "disabled";
		};

		ppmu_d0_general: ppmu_d0_general@10490000 {
			compatible = "samsung,exynos-ppmu-v2";
			reg = <0x10490000 0x2000>;
			status = "disabled";
		};

		ppmu_d0_rt: ppmu_d0_rt@104a0000 {
			compatible = "samsung,exynos-ppmu-v2";
			reg = <0x104a0000 0x2000>;
			status = "disabled";
		};

		ppmu_d1_cpu: ppmu_d1_cpu@104b0000 {
			compatible = "samsung,exynos-ppmu-v2";
			reg = <0x104b0000 0x2000>;
			status = "disabled";
		};

		ppmu_d1_general: ppmu_d1_general@104c0000 {
			compatible = "samsung,exynos-ppmu-v2";
			reg = <0x104c0000 0x2000>;
			status = "disabled";
		};

		ppmu_d1_rt: ppmu_d1_rt@104d0000 {
			compatible = "samsung,exynos-ppmu-v2";
			reg = <0x104d0000 0x2000>;
			status = "disabled";
		};

		decon: decon@13800000 {
			compatible = "samsung,exynos5433-decon";
			reg = <0x13800000 0x2104>;
			clocks = <&cmu_disp CLK_ACLK_DECON>,
				 <&cmu_disp CLK_ACLK_SMMU_DECON0X>,
				 <&cmu_disp CLK_ACLK_XIU_DECON0X>,
				 <&cmu_disp CLK_PCLK_SMMU_DECON0X>,
				 <&cmu_disp CLK_SCLK_DECON_VCLK>,
				 <&cmu_disp CLK_SCLK_DECON_ECLK>;
			clock-names = "aclk_decon", "aclk_smmu_decon0x",
				      "aclk_xiu_decon0x", "pclk_smmu_decon0x",
				      "sclk_decon_vclk", "sclk_decon_eclk";
			interrupt-names = "fifo", "vsync", "lcd_sys";
			interrupts = <0 201 0>, <0 202 0>, <0 203 0>;
			power-domains = <&pd_disp>;
			status = "disabled";
			iommus = <&sysmmu_decon0x>, <&sysmmu_decon1x>;
			iommu-names = "m0", "m1";

			ports {
				#address-cells = <1>;
				#size-cells = <0>;

				port@0 {
					reg = <0>;
					decon_to_mic: endpoint {
						remote-endpoint = <&mic_to_decon>;
					};
				};
			};
		};

		dsi: dsi@13900000 {
			compatible = "samsung,exynos5433-mipi-dsi";
			reg = <0x13900000 0xC0>;
			interrupts = <0 205 0>;
			phys = <&mipi_phy 1>;
			phy-names = "dsim";
			clocks = <&cmu_disp CLK_PCLK_DSIM0>,
				 <&cmu_disp CLK_PHYCLK_MIPIDPHY0_BITCLKDIV8>,
				 <&cmu_disp CLK_PHYCLK_MIPIDPHY0_RXCLKESC0>,
				 <&cmu_disp CLK_SCLK_RGB_VCLK_TO_DSIM0>,
				 <&cmu_disp CLK_SCLK_DSIM0>;
			clock-names = "bus_clk",
				      "phyclk_mipidphy0_bitclkdiv8",
				      "phyclk_mipidphy0_rxclkesc0",
				      "sclk_rgb_vclk_to_dsim0",
				      "sclk_mipi";
			power-domains = <&pd_disp>;
			status = "disabled";
			#address-cells = <1>;
			#size-cells = <0>;

			ports {
				#address-cells = <1>;
				#size-cells = <0>;

				port@0 {
					reg = <0>;
					dsi_to_mic: endpoint {
						remote-endpoint = <&mic_to_dsi>;
					};
				};
			};
		};

		mic: mic@13930000 {
			compatible = "samsung,exynos5433-mic";
			reg = <0x13930000 0x48>;
			clocks = <&cmu_disp CLK_PCLK_MIC0>,
				 <&cmu_disp CLK_SCLK_RGB_VCLK_TO_MIC0>;
			clock-names = "pclk_mic0", "sclk_rgb_vclk_to_mic0";
			samsung,disp-syscon = <&syscon_disp>;
			status = "disabled";

			ports {
				#address-cells = <1>;
				#size-cells = <0>;

				port@0 {
					reg = <0>;
					mic_to_decon: endpoint {
						remote-endpoint = <&decon_to_mic>;
					};
				};

				port@1 {
					reg = <1>;
					mic_to_dsi: endpoint {
						remote-endpoint = <&dsi_to_mic>;
					};
				};
			};
		};

		lpass {
			compatible = "samsung,exynos5433-lpass";
			reg = <0x11400000 0x100>;
			samsung,pmu-syscon = <&pmu_system_controller>;
		};

		gsc_0: video-scaler@13C00000 {
			compatible = "samsung,exynos5433-gsc";
			reg = <0x13c00000 0x1000>;
			interrupts = <0 297 0>;
			clocks = <&cmu_gscl CLK_PCLK_GSCL0>,
				 <&cmu_gscl CLK_ACLK_GSCL0>,
				 <&cmu_gscl CLK_ACLK_XIU_GSCLX>,
				 <&cmu_gscl CLK_ACLK_GSCLBEND_333>;
			clock-names = "pclk",
				      "aclk",
				      "aclk_xiu",
				      "aclk_gsclbend";
			assigned-clocks = <&cmu_gscl CLK_MOUT_ACLK_GSCL_111_USER>,
					  <&cmu_gscl CLK_MOUT_ACLK_GSCL_333_USER>;
			assigned-clock-parents = <&cmu_top CLK_ACLK_GSCL_111>,
						 <&cmu_top CLK_ACLK_GSCL_333>;
			iommus = <&sysmmu_gscl0>;
		};

		gsc_1: video-scaler@13C10000 {
			compatible = "samsung,exynos5433-gsc";
			reg = <0x13c10000 0x1000>;
			interrupts = <0 298 0>;
			clocks = <&cmu_gscl CLK_PCLK_GSCL1>,
				 <&cmu_gscl CLK_ACLK_GSCL1>,
				 <&cmu_gscl CLK_ACLK_XIU_GSCLX>,
				 <&cmu_gscl CLK_ACLK_GSCLBEND_333>;
			clock-names = "pclk",
				      "aclk",
				      "aclk_xiu",
				      "aclk_gsclbend";
			assigned-clocks = <&cmu_gscl CLK_MOUT_ACLK_GSCL_111_USER>,
					  <&cmu_gscl CLK_MOUT_ACLK_GSCL_333_USER>;
			assigned-clock-parents = <&cmu_top CLK_ACLK_GSCL_111>,
						 <&cmu_top CLK_ACLK_GSCL_333>;
			iommus = <&sysmmu_gscl1>;
		};

		gsc_2: video-scaler@13C20000 {
			compatible = "samsung,exynos5433-gsc";
			reg = <0x13c20000 0x1000>;
			interrupts = <0 299 0>;
			clocks = <&cmu_gscl CLK_PCLK_GSCL2>,
				 <&cmu_gscl CLK_ACLK_GSCL2>,
				 <&cmu_gscl CLK_ACLK_XIU_GSCLX>,
				 <&cmu_gscl CLK_ACLK_GSCLBEND_333>;
			clock-names = "pclk",
				      "aclk",
				      "aclk_xiu",
				      "aclk_gsclbend";
			assigned-clocks = <&cmu_gscl CLK_MOUT_ACLK_GSCL_111_USER>,
					  <&cmu_gscl CLK_MOUT_ACLK_GSCL_333_USER>;
			assigned-clock-parents = <&cmu_top CLK_ACLK_GSCL_111>,
						 <&cmu_top CLK_ACLK_GSCL_333>;
			iommus = <&sysmmu_gscl2>;
		};

		mfc-bus {
			compatible = "simple-bus";
			#address-cells = <1>;
			#size-cells = <1>;
			ranges;
			dma-ranges = <0x10000000 0x10000000 0x20000000>;

			mfc_0: mfc@152E0000 {
				compatible = "samsung,exynos5433-mfc";
				reg = <0x152E0000 0x10000>;
				interrupts = <0 358 0>;
				clocks = <&cmu_mfc CLK_PCLK_MFC>,
					 <&cmu_mfc CLK_ACLK_MFC>,
					 <&cmu_mfc CLK_ACLK_XIU_MFCX>;
				clock-names = "pclk",
					      "aclk",
					      "aclk_xiu";
				assigned-clocks = <&cmu_mfc CLK_MOUT_ACLK_MFC_400_USER>;
				assigned-clock-parents = <&cmu_top CLK_ACLK_MFC_400>;
				iommus = <&sysmmu_mfc_0>, <&sysmmu_mfc_1>;
				iommu-names = "left", "right";
			};
		};

		jpeg: jpeg@15020000 {
			compatible = "samsung,exynos5433-jpeg";
			reg = <0x15020000 0x10000>;
			interrupts = <0 411 0>;
			clock-names = "pclk",
				      "aclk",
				      "aclk_xiu",
				      "sclk";
			clocks = <&cmu_mscl CLK_PCLK_JPEG>,
				 <&cmu_mscl CLK_ACLK_JPEG>,
				 <&cmu_mscl CLK_ACLK_XIU_MSCLX>,
				 <&cmu_mscl CLK_SCLK_JPEG>;
			assigned-clocks = <&cmu_mscl CLK_MOUT_ACLK_MSCL_400_USER>,
					  <&cmu_mscl CLK_MOUT_SCLK_JPEG_USER>,
					  <&cmu_mscl CLK_MOUT_SCLK_JPEG>,
					  <&cmu_top CLK_MOUT_SCLK_JPEG_A>;
			assigned-clock-parents = <&cmu_top CLK_ACLK_MSCL_400>,
						 <&cmu_top CLK_SCLK_JPEG_MSCL>,
						 <&cmu_mscl CLK_MOUT_SCLK_JPEG_USER>,
						 <&cmu_top CLK_MOUT_BUS_PLL_USER>;
			iommus = <&sysmmu_jpeg>;
		};

		sysmmu_gscl0: sysmmu@0x13C80000 {
			compatible = "samsung,exynos-sysmmu";
			reg = <0x13C80000 0x1000>;
			interrupts = <0 288 0>;
			clock-names = "aclk", "pclk";
			clocks = <&cmu_gscl CLK_ACLK_SMMU_GSCL0>, <&cmu_gscl CLK_PCLK_SMMU_GSCL0>;
			#iommu-cells = <0>;
		};

		sysmmu_gscl1: sysmmu@0x13C90000 {
			compatible = "samsung,exynos-sysmmu";
			reg = <0x13C90000 0x1000>;
			interrupts = <0 290 0>;
			clock-names = "aclk", "pclk";
			clocks = <&cmu_gscl CLK_ACLK_SMMU_GSCL1>, <&cmu_gscl CLK_PCLK_SMMU_GSCL1>;
			#iommu-cells = <0>;
		};

		sysmmu_gscl2: sysmmu@0x13CA0000 {
			compatible = "samsung,exynos-sysmmu";
			reg = <0x13CA0000 0x1000>;
			interrupts = <0 292 0>;
			clock-names = "aclk", "pclk";
			clocks = <&cmu_gscl CLK_ACLK_SMMU_GSCL2>, <&cmu_gscl CLK_PCLK_SMMU_GSCL2>;
			#iommu-cells = <0>;
		};

		sysmmu_decon0x: sysmmu@0x13A00000 {
			compatible = "samsung,exynos-sysmmu";
			reg = <0x13A00000 0x1000>;
			interrupts = <0 192 0>;
			clock-names = "pclk", "aclk";
			clocks = <&cmu_disp CLK_PCLK_SMMU_DECON0X>, <&cmu_disp CLK_ACLK_SMMU_DECON0X>;
			#iommu-cells = <0>;
		};

		sysmmu_decon1x: sysmmu@0x13A10000 {
			compatible = "samsung,exynos-sysmmu";
			reg = <0x13A10000 0x1000>;
			interrupts = <0 194 0>;
			clock-names = "pclk", "aclk";
			clocks = <&cmu_disp CLK_PCLK_SMMU_DECON1X>, <&cmu_disp CLK_ACLK_SMMU_DECON1X>;
			#iommu-cells = <0>;
		};

		sysmmu_mfc_0: sysmmu@0x15200000 {
			compatible = "samsung,exynos-sysmmu";
			reg = <0x15200000 0x1000>;
			interrupts = <0 352 0>;
			clock-names = "pclk", "aclk";
			clocks = <&cmu_mfc CLK_PCLK_SMMU_MFC_0>, <&cmu_mfc CLK_ACLK_SMMU_MFC_0>;
			#iommu-cells = <0>;
		};

		sysmmu_mfc_1: sysmmu@0x15210000 {
			compatible = "samsung,exynos-sysmmu";
			reg = <0x15210000 0x1000>;
			interrupts = <0 354 0>;
			clock-names = "pclk", "aclk";
			clocks = <&cmu_mfc CLK_PCLK_SMMU_MFC_1>, <&cmu_mfc CLK_ACLK_SMMU_MFC_1>;
			#iommu-cells = <0>;
		};

		sysmmu_jpeg: sysmmu@0x15060000 {
			compatible = "samsung,exynos-sysmmu";
			reg = <0x15060000 0x1000>;
			interrupts = <0 408 0>;
			clock-names = "pclk", "aclk";
			clocks = <&cmu_mscl CLK_PCLK_SMMU_JPEG>, <&cmu_mscl CLK_ACLK_SMMU_JPEG>;
			#iommu-cells = <0>;
		};

		pcie: pcie@15700000 {
			compatible = "samsung,exynos5433-pcie";
			#address-cells = <3>;
			#size-cells = <2>;
			device_type = "pci";
			clock-names = "pcie", "pcie_bus";
			clocks = <&cmu_fsys CLK_PCIE>,
				 <&cmu_fsys CLK_PCIE_PHY>;
			assigned-clocks = <&cmu_fsys CLK_MOUT_SCLK_PCIE_100_USER>,
				<&cmu_top CLK_MOUT_SCLK_PCIE_100>;
			assigned-clock-parents = <&cmu_top CLK_SCLK_PCIE_100_FSYS>,
				<&cmu_top CLK_MOUT_BUS_PLL_USER>;
			assigned-clock-rates = <0>, <100000000>;
			interrupts = <0 245 0>;
			num-lanes = <1>;
			reg = <0x156b0000 0x1000>, <0x15680000 0x1000>, <0x156f0000 0x2000>;
			reg-names = "elbi", "phy", "block";
			reset-gpio = <&gpr3 5 1>;
			wlanen-gpio = <&gpj2 0 1>;
			samsung,pmureg-phandle = <&pmu_system_controller>;
			pinctrl-names = "default";
			pinctrl-0 = <&pcie_bus &pcie_clkreq &pcie_wake>;
			ranges = <0x00000800 0 0x0c000000 0x0c000000 0 0x00001000   /* configuration space */
				  0x81000000 0 0          0x0c001000 0 0x00010000   /* downstream I/O */
				  0x82000000 0 0x0c011000 0x0c011000 0 0x3feefff>; /* non-prefetchable memory */
		};

		wlan {
			compatible = "samsung,brcm-wlan";
			gpios = <&gpj2 0 0x1 &gpf3 1 0x1>;
			pinctrl-names = "default";
			pinctrl-0 = <&cfg_wlanen &wlan_host_wake>;
			status = "okay";
		};
	};

	timer {
		compatible = "arm,armv8-timer";
		interrupts = <1 13 0xff04>,
			     <1 14 0xff04>,
			     <1 11 0xff04>,
			     <1 10 0xff04>;
		clock-frequency = <24000000>;
	};
};

#include "exynos5433-pinctrl.dtsi"
#include "exynos5433-tmu.dtsi"
#include "exynos5433-memory-bus.dtsi"
